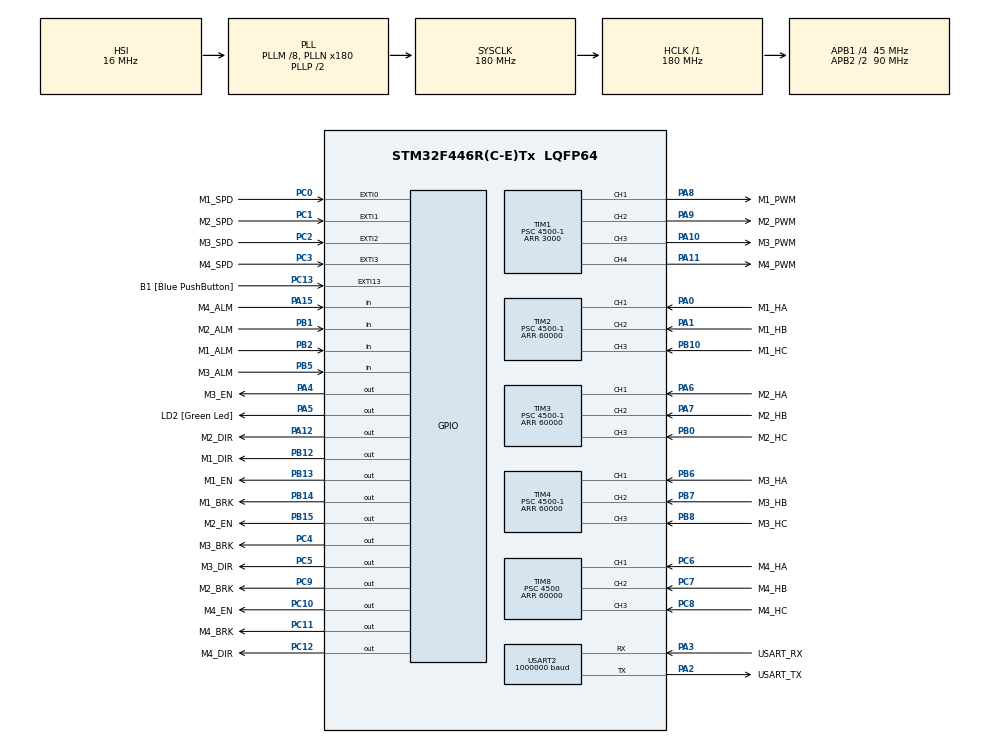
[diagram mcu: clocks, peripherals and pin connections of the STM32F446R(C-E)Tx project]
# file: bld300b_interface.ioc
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Dma.Request0=USART2_RX
Dma.Request1=USART2_TX
Dma.USART2_RX.0.Direction=DMA_PERIPH_TO_MEMORY
Dma.USART2_RX.0.FIFOMode=DMA_FIFOMODE_DISABLE
Dma.USART2_RX.0.Instance=DMA1_Stream5
Dma.USART2_RX.0.MemDataAlignment=DMA_MDATAALIGN_BYTE
Dma.USART2_RX.0.MemInc=DMA_MINC_ENABLE
Dma.USART2_RX.0.Mode=DMA_NORMAL
Dma.USART2_RX.0.PeriphDataAlignment=DMA_PDATAALIGN_BYTE
Dma.USART2_RX.0.PeriphInc=DMA_PINC_DISABLE
Dma.USART2_RX.0.Priority=DMA_PRIORITY_LOW
Dma.USART2_TX.1.Direction=DMA_MEMORY_TO_PERIPH
Dma.USART2_TX.1.FIFOMode=DMA_FIFOMODE_DISABLE
Dma.USART2_TX.1.Instance=DMA1_Stream6
Dma.USART2_TX.1.MemDataAlignment=DMA_MDATAALIGN_BYTE
Dma.USART2_TX.1.MemInc=DMA_MINC_ENABLE
Dma.USART2_TX.1.Mode=DMA_NORMAL
Dma.USART2_TX.1.PeriphDataAlignment=DMA_PDATAALIGN_BYTE
Dma.USART2_TX.1.PeriphInc=DMA_PINC_DISABLE
Dma.USART2_TX.1.Priority=DMA_PRIORITY_LOW
Mcu.Family=STM32F4
Mcu.Name=STM32F446R(C-E)Tx
Mcu.Package=LQFP64
NVIC.DMA1_Stream5_IRQn=true\:0\:0\:false\:false\:true\:false\:true
NVIC.DMA1_Stream6_IRQn=true\:0\:0\:false\:false\:true\:false\:true
NVIC.EXTI0_IRQn=true\:1\:0\:true\:false\:true\:true\:true
NVIC.EXTI1_IRQn=true\:1\:0\:true\:false\:true\:true\:true
NVIC.EXTI2_IRQn=true\:1\:0\:true\:false\:true\:true\:true
NVIC.EXTI3_IRQn=true\:1\:0\:true\:false\:true\:true\:true
NVIC.PriorityGroup=NVIC_PRIORITYGROUP_2
NVIC.TIM2_IRQn=true\:2\:0\:true\:false\:true\:true\:true
NVIC.TIM3_IRQn=true\:2\:0\:true\:false\:true\:true\:true
NVIC.TIM4_IRQn=true\:2\:0\:true\:false\:true\:true\:true
NVIC.TIM8_TRG_COM_TIM14_IRQn=true\:2\:0\:true\:false\:true\:false\:true
NVIC.TIM8_UP_TIM13_IRQn=true\:2\:0\:true\:false\:true\:false\:true
NVIC.USART2_IRQn=true\:1\:0\:true\:false\:true\:true\:true
PA0-WKUP.GPIO_Label=M1_HA
PA0-WKUP.Signal=S_TIM2_CH1_ETR
PA1.GPIO_Label=M1_HB
PA1.Signal=S_TIM2_CH2
PA10.GPIO_Label=M3_PWM
PA10.GPIO_PuPd=GPIO_PULLDOWN
PA10.Signal=S_TIM1_CH3
PA11.GPIO_Label=M4_PWM
PA11.GPIO_PuPd=GPIO_PULLDOWN
PA11.Signal=S_TIM1_CH4
PA12.GPIO_Label=M2_DIR
PA12.Signal=GPIO_Output
PA13.GPIO_Label=TMS
PA13.Mode=Trace_Asynchronous_SW
PA13.Signal=SYS_JTMS-SWDIO
PA14.GPIO_Label=TCK
PA14.Mode=Trace_Asynchronous_SW
PA14.Signal=SYS_JTCK-SWCLK
PA15.GPIO_Label=M4_ALM
PA15.Signal=GPIO_Input
PA2.GPIO_Label=USART_TX
PA2.Mode=Asynchronous
PA2.Signal=USART2_TX
PA3.GPIO_Label=USART_RX
PA3.Mode=Asynchronous
PA3.Signal=USART2_RX
PA4.GPIO_Label=M3_EN
PA4.Signal=GPIO_Output
PA5.GPIO_Label=LD2 [Green Led]
PA5.Signal=GPIO_Output
PA6.GPIO_Label=M2_HA
PA6.Signal=S_TIM3_CH1
PA7.GPIO_Label=M2_HB
PA7.Signal=S_TIM3_CH2
PA8.GPIO_Label=M1_PWM
PA8.GPIO_PuPd=GPIO_PULLDOWN
PA8.Signal=S_TIM1_CH1
PA9.GPIO_Label=M2_PWM
PA9.GPIO_PuPd=GPIO_PULLDOWN
PA9.Signal=S_TIM1_CH2
PB0.GPIO_Label=M2_HC
PB0.Signal=S_TIM3_CH3
PB1.GPIO_Label=M2_ALM
PB1.Signal=GPIO_Input
PB10.GPIO_Label=M1_HC
PB10.Signal=S_TIM2_CH3
PB12.GPIO_Label=M1_DIR
PB12.Signal=GPIO_Output
PB13.GPIO_Label=M1_EN
PB13.GPIO_PuPd=GPIO_PULLDOWN
PB13.Signal=GPIO_Output
PB14.GPIO_Label=M1_BRK
PB14.GPIO_PuPd=GPIO_PULLDOWN
PB14.Signal=GPIO_Output
PB15.GPIO_Label=M2_EN
PB15.Signal=GPIO_Output
PB2.GPIO_Label=M1_ALM
PB2.Signal=GPIO_Input
PB3.GPIO_Label=SWO
PB3.Mode=Trace_Asynchronous_SW
PB3.Signal=SYS_JTDO-SWO
PB5.GPIO_Label=M3_ALM
PB5.Signal=GPIO_Input
PB6.GPIO_Label=M3_HA
PB6.Signal=S_TIM4_CH1
PB7.GPIO_Label=M3_HB
PB7.Signal=S_TIM4_CH2
PB8.GPIO_Label=M3_HC
PB8.Signal=S_TIM4_CH3
PC0.GPIO_Label=M1_SPD
PC0.GPIO_ModeDefaultEXTI=GPIO_MODE_IT_RISING
PC0.GPIO_PuPd=GPIO_PULLDOWN
PC0.Signal=GPXTI0
PC1.GPIO_Label=M2_SPD
PC1.GPIO_ModeDefaultEXTI=GPIO_MODE_IT_RISING
PC1.GPIO_PuPd=GPIO_PULLDOWN
PC1.Signal=GPXTI1
PC10.GPIO_Label=M4_EN
PC10.Signal=GPIO_Output
PC11.GPIO_Label=M4_BRK
PC11.Signal=GPIO_Output
PC12.GPIO_Label=M4_DIR
PC12.Signal=GPIO_Output
PC13.GPIO_Label=B1 [Blue PushButton]
PC13.GPIO_ModeDefaultEXTI=GPIO_MODE_IT_FALLING
PC13.Signal=GPXTI13
PC14-OSC32_IN.Mode=LSE-External-Oscillator
PC14-OSC32_IN.Signal=RCC_OSC32_IN
PC15-OSC32_OUT.Mode=LSE-External-Oscillator
PC15-OSC32_OUT.Signal=RCC_OSC32_OUT
PC2.GPIO_Label=M3_SPD
PC2.GPIO_ModeDefaultEXTI=GPIO_MODE_IT_RISING
PC2.GPIO_PuPd=GPIO_PULLDOWN
PC2.Signal=GPXTI2
PC3.GPIO_Label=M4_SPD
PC3.GPIO_ModeDefaultEXTI=GPIO_MODE_IT_RISING
PC3.GPIO_PuPd=GPIO_PULLDOWN
PC3.Signal=GPXTI3
PC4.GPIO_Label=M3_BRK
PC4.Signal=GPIO_Output
PC5.GPIO_Label=M3_DIR
PC5.Signal=GPIO_Output
PC6.GPIO_Label=M4_HA
PC6.Signal=S_TIM8_CH1
PC7.GPIO_Label=M4_HB
PC7.Signal=S_TIM8_CH2
PC8.GPIO_Label=M4_HC
PC8.Signal=S_TIM8_CH3
PC9.GPIO_Label=M2_BRK
PC9.Signal=GPIO_Output
PH0-OSC_IN.Mode=HSE-External-Oscillator
PH0-OSC_IN.Signal=RCC_OSC_IN
PH1-OSC_OUT.Mode=HSE-External-Oscillator
PH1-OSC_OUT.Signal=RCC_OSC_OUT
ProjectManager.HeapSize=0x200
ProjectManager.StackSize=0x400
ProjectManager.TargetToolchain=TrueSTUDIO
RCC.AHBFreq_Value=180000000
RCC.APB1CLKDivider=RCC_HCLK_DIV4
RCC.APB1Freq_Value=45000000
RCC.APB1TimFreq_Value=90000000
RCC.APB2CLKDivider=RCC_HCLK_DIV2
RCC.APB2Freq_Value=90000000
RCC.APB2TimFreq_Value=180000000
RCC.CortexFreq_Value=180000000
RCC.FLatency-AdvancedSettings=FLASH_LATENCY_5
RCC.HCLKFreq_Value=180000000
RCC.HSE_VALUE=8000000
RCC.HSI_VALUE=16000000
RCC.PLLM=8
RCC.PLLN=180
RCC.SYSCLKFreq_VALUE=180000000
RCC.SYSCLKSource=RCC_SYSCLKSOURCE_PLLCLK
RCC.USBFreq_Value=180000000
RCC.VCOOutputFreq_Value=360000000
SH.S_TIM1_CH1.0=TIM1_CH1,PWM Generation1 CH1
SH.S_TIM1_CH2.0=TIM1_CH2,PWM Generation2 CH2
SH.S_TIM1_CH3.0=TIM1_CH3,PWM Generation3 CH3
SH.S_TIM1_CH4.0=TIM1_CH4,PWM Generation4 CH4
SH.S_TIM2_CH1_ETR.0=TIM2_CH1,Xored_Inputs_Hall_Sensor_Interface
SH.S_TIM2_CH2.0=TIM2_CH2,Xored_Inputs_Hall_Sensor_Interface
SH.S_TIM2_CH3.0=TIM2_CH3,Xored_Inputs_Hall_Sensor_Interface
SH.S_TIM3_CH1.0=TIM3_CH1,Xored_Inputs_Hall_Sensor_Interface
SH.S_TIM3_CH2.0=TIM3_CH2,Xored_Inputs_Hall_Sensor_Interface
SH.S_TIM3_CH3.0=TIM3_CH3,Xored_Inputs_Hall_Sensor_Interface
SH.S_TIM4_CH1.0=TIM4_CH1,Xored_Inputs_Hall_Sensor_Interface
SH.S_TIM4_CH2.0=TIM4_CH2,Xored_Inputs_Hall_Sensor_Interface
SH.S_TIM4_CH3.0=TIM4_CH3,Xored_Inputs_Hall_Sensor_Interface
SH.S_TIM8_CH1.0=TIM8_CH1,Xored_Inputs_Hall_Sensor_Interface
SH.S_TIM8_CH2.0=TIM8_CH2,Xored_Inputs_Hall_Sensor_Interface
SH.S_TIM8_CH3.0=TIM8_CH3,Xored_Inputs_Hall_Sensor_Interface
TIM1.Channel-PWM\ Generation1\ CH1=TIM_CHANNEL_1
TIM1.Channel-PWM\ Generation2\ CH2=TIM_CHANNEL_2
TIM1.Channel-PWM\ Generation3\ CH3=TIM_CHANNEL_3
TIM1.Channel-PWM\ Generation4\ CH4=TIM_CHANNEL_4
TIM1.ClockDivision=TIM_CLOCKDIVISION_DIV4
TIM1.Period=3000
TIM1.Prescaler=4500-1
TIM1.Pulse-PWM\ Generation1\ CH1=750
TIM2.ClockDivision=TIM_CLOCKDIVISION_DIV4
TIM2.IC1Filter=3
TIM2.Period=60000
TIM2.Prescaler=4500-1
TIM3.ClockDivision=TIM_CLOCKDIVISION_DIV4
TIM3.IC1Filter=3
TIM3.Period=60000
TIM3.Prescaler=4500-1
TIM4.ClockDivision=TIM_CLOCKDIVISION_DIV4
TIM4.IC1Filter=3
TIM4.Period=60000
TIM4.Prescaler=4500-1
TIM5.ClockDivision=TIM_CLOCKDIVISION_DIV4
TIM5.Period=0xffffffff
TIM5.Prescaler=45-1
TIM8.ClockDivision=TIM_CLOCKDIVISION_DIV4
TIM8.IC1Filter=3
TIM8.Period=60000
TIM8.Prescaler=4500
USART2.BaudRate=1000000
USART2.VirtualMode=VM_ASYNC
VP_TIM5_VS_ClockSourceINT.Mode=Internal
board=NUCLEO-F446RE

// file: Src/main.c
/* USER CODE BEGIN Header */
/**
  ******************************************************************************
  * @file           : main.c
  * @brief          : Main program body
  ******************************************************************************
  * @attention
  *
  * <h2><center>&copy; Copyright (c) 2019 STMicroelectronics.
  * All rights reserved.</center></h2>
  *
  * This software component is licensed by ST under BSD 3-Clause license,
  * the "License"; You may not use this file except in compliance with the
  * License. You may obtain a copy of the License at:
  *                        opensource.org/licenses/BSD-3-Clause
  *
  ******************************************************************************
  */
/* USER CODE END Header */

#include "main.h"

/* USER CODE BEGIN Includes */
#include "firmware.h"
/* USER CODE END Includes */

TIM_HandleTypeDef htim1;
TIM_HandleTypeDef htim2;
TIM_HandleTypeDef htim3;
TIM_HandleTypeDef htim4;
TIM_HandleTypeDef htim5;
TIM_HandleTypeDef htim8;

UART_HandleTypeDef huart2;

void SystemClock_Config(void);
static void MX_GPIO_Init(void);
static void MX_USART2_UART_Init(void);
static void MX_TIM1_Init(void);
static void MX_TIM2_Init(void);
static void MX_TIM3_Init(void);
static void MX_TIM4_Init(void);
static void MX_TIM8_Init(void);
static void MX_TIM5_Init(void);

int main(void)
{

  /* MCU Configuration--------------------------------------------------------*/

  /* Reset of all peripherals, Initializes the Flash interface and the Systick. */
  HAL_Init();

  /* Configure the system clock */
  SystemClock_Config();

  /* Initialize all configured peripherals */
  MX_GPIO_Init();
  MX_USART2_UART_Init();
  MX_TIM1_Init();
  MX_TIM2_Init();
  MX_TIM3_Init();
  MX_TIM4_Init();
  MX_TIM8_Init();
  MX_TIM5_Init();
  /* USER CODE BEGIN 2 */

  /* Init firmware */
  Firmware_Init();

  /* USER CODE END 2 */

  /* Infinite loop */
  /* USER CODE BEGIN WHILE */
  while (1)
  {
    /* Update firmware */
    Firmware_Update();
    /* USER CODE END WHILE */

  }
}

void SystemClock_Config(void)
{
  RCC_OscInitTypeDef RCC_OscInitStruct = {0};
  RCC_ClkInitTypeDef RCC_ClkInitStruct = {0};

  /** Configure the main internal regulator output voltage
  */
  __HAL_RCC_PWR_CLK_ENABLE();
  __HAL_PWR_VOLTAGESCALING_CONFIG(PWR_REGULATOR_VOLTAGE_SCALE1);
  /** Initializes the CPU, AHB and APB busses clocks
  */
  RCC_OscInitStruct.OscillatorType = RCC_OSCILLATORTYPE_HSI;
  RCC_OscInitStruct.HSIState = RCC_HSI_ON;
  RCC_OscInitStruct.HSICalibrationValue = RCC_HSICALIBRATION_DEFAULT;
  RCC_OscInitStruct.PLL.PLLState = RCC_PLL_ON;
  RCC_OscInitStruct.PLL.PLLSource = RCC_PLLSOURCE_HSI;
  RCC_OscInitStruct.PLL.PLLM = 8;
  RCC_OscInitStruct.PLL.PLLN = 180;
  RCC_OscInitStruct.PLL.PLLP = RCC_PLLP_DIV2;
  RCC_OscInitStruct.PLL.PLLQ = 2;
  RCC_OscInitStruct.PLL.PLLR = 2;
  if (HAL_RCC_OscConfig(&RCC_OscInitStruct) != HAL_OK)
  {
    Error_Handler();
  }
  /** Activate the Over-Drive mode
  */
  if (HAL_PWREx_EnableOverDrive() != HAL_OK)
  {
    Error_Handler();
  }
  /** Initializes the CPU, AHB and APB busses clocks
  */
  RCC_ClkInitStruct.ClockType = RCC_CLOCKTYPE_HCLK|RCC_CLOCKTYPE_SYSCLK
                              |RCC_CLOCKTYPE_PCLK1|RCC_CLOCKTYPE_PCLK2;
  RCC_ClkInitStruct.SYSCLKSource = RCC_SYSCLKSOURCE_PLLCLK;
  RCC_ClkInitStruct.AHBCLKDivider = RCC_SYSCLK_DIV1;
  RCC_ClkInitStruct.APB1CLKDivider = RCC_HCLK_DIV4;
  RCC_ClkInitStruct.APB2CLKDivider = RCC_HCLK_DIV2;

  if (HAL_RCC_ClockConfig(&RCC_ClkInitStruct, FLASH_LATENCY_5) != HAL_OK)
  {
    Error_Handler();
  }
}

static void MX_TIM1_Init(void)
{

  TIM_MasterConfigTypeDef sMasterConfig = {0};
  TIM_OC_InitTypeDef sConfigOC = {0};
  TIM_BreakDeadTimeConfigTypeDef sBreakDeadTimeConfig = {0};

  htim1.Instance = TIM1;
  htim1.Init.Prescaler = 4500;
  htim1.Init.CounterMode = TIM_COUNTERMODE_UP;
  htim1.Init.Period = 3000;
  htim1.Init.ClockDivision = TIM_CLOCKDIVISION_DIV4;
  htim1.Init.RepetitionCounter = 0;
  htim1.Init.AutoReloadPreload = TIM_AUTORELOAD_PRELOAD_DISABLE;
  if (HAL_TIM_PWM_Init(&htim1) != HAL_OK)
  {
    Error_Handler();
  }
  sMasterConfig.MasterOutputTrigger = TIM_TRGO_RESET;
  sMasterConfig.MasterSlaveMode = TIM_MASTERSLAVEMODE_DISABLE;
  if (HAL_TIMEx_MasterConfigSynchronization(&htim1, &sMasterConfig) != HAL_OK)
  {
    Error_Handler();
  }
  sConfigOC.OCMode = TIM_OCMODE_PWM1;
  sConfigOC.Pulse = 750;
  sConfigOC.OCPolarity = TIM_OCPOLARITY_HIGH;
  sConfigOC.OCNPolarity = TIM_OCNPOLARITY_HIGH;
  sConfigOC.OCFastMode = TIM_OCFAST_DISABLE;
  sConfigOC.OCIdleState = TIM_OCIDLESTATE_RESET;
  sConfigOC.OCNIdleState = TIM_OCNIDLESTATE_RESET;
  if (HAL_TIM_PWM_ConfigChannel(&htim1, &sConfigOC, TIM_CHANNEL_1) != HAL_OK)
  {
    Error_Handler();
  }
  sConfigOC.Pulse = 0;
  if (HAL_TIM_PWM_ConfigChannel(&htim1, &sConfigOC, TIM_CHANNEL_2) != HAL_OK)
  {
    Error_Handler();
  }
  if (HAL_TIM_PWM_ConfigChannel(&htim1, &sConfigOC, TIM_CHANNEL_3) != HAL_OK)
  {
    Error_Handler();
  }
  if (HAL_TIM_PWM_ConfigChannel(&htim1, &sConfigOC, TIM_CHANNEL_4) != HAL_OK)
  {
    Error_Handler();
  }
  sBreakDeadTimeConfig.OffStateRunMode = TIM_OSSR_DISABLE;
  sBreakDeadTimeConfig.OffStateIDLEMode = TIM_OSSI_DISABLE;
  sBreakDeadTimeConfig.LockLevel = TIM_LOCKLEVEL_OFF;
  sBreakDeadTimeConfig.DeadTime = 0;
  sBreakDeadTimeConfig.BreakState = TIM_BREAK_DISABLE;
  sBreakDeadTimeConfig.BreakPolarity = TIM_BREAKPOLARITY_HIGH;
  sBreakDeadTimeConfig.AutomaticOutput = TIM_AUTOMATICOUTPUT_DISABLE;
  if (HAL_TIMEx_ConfigBreakDeadTime(&htim1, &sBreakDeadTimeConfig) != HAL_OK)
  {
    Error_Handler();
  }
  HAL_TIM_MspPostInit(&htim1);

}

static void MX_TIM2_Init(void)
{

  TIM_HallSensor_InitTypeDef sConfig = {0};
  TIM_MasterConfigTypeDef sMasterConfig = {0};

  htim2.Instance = TIM2;
  htim2.Init.Prescaler = 4500;
  htim2.Init.CounterMode = TIM_COUNTERMODE_UP;
  htim2.Init.Period = 60000;
  htim2.Init.ClockDivision = TIM_CLOCKDIVISION_DIV4;
  htim2.Init.AutoReloadPreload = TIM_AUTORELOAD_PRELOAD_DISABLE;
  sConfig.IC1Polarity = TIM_ICPOLARITY_RISING;
  sConfig.IC1Prescaler = TIM_ICPSC_DIV1;
  sConfig.IC1Filter = 3;
  sConfig.Commutation_Delay = 0;
  if (HAL_TIMEx_HallSensor_Init(&htim2, &sConfig) != HAL_OK)
  {
    Error_Handler();
  }
  sMasterConfig.MasterOutputTrigger = TIM_TRGO_OC2REF;
  sMasterConfig.MasterSlaveMode = TIM_MASTERSLAVEMODE_DISABLE;
  if (HAL_TIMEx_MasterConfigSynchronization(&htim2, &sMasterConfig) != HAL_OK)
  {
    Error_Handler();
  }

}

static void MX_TIM3_Init(void)
{

  TIM_HallSensor_InitTypeDef sConfig = {0};
  TIM_MasterConfigTypeDef sMasterConfig = {0};

  htim3.Instance = TIM3;
  htim3.Init.Prescaler = 4500;
  htim3.Init.CounterMode = TIM_COUNTERMODE_UP;
  htim3.Init.Period = 60000;
  htim3.Init.ClockDivision = TIM_CLOCKDIVISION_DIV4;
  htim3.Init.AutoReloadPreload = TIM_AUTORELOAD_PRELOAD_DISABLE;
  sConfig.IC1Polarity = TIM_ICPOLARITY_RISING;
  sConfig.IC1Prescaler = TIM_ICPSC_DIV1;
  sConfig.IC1Filter = 3;
  sConfig.Commutation_Delay = 0;
  if (HAL_TIMEx_HallSensor_Init(&htim3, &sConfig) != HAL_OK)
  {
    Error_Handler();
  }
  sMasterConfig.MasterOutputTrigger = TIM_TRGO_OC2REF;
  sMasterConfig.MasterSlaveMode = TIM_MASTERSLAVEMODE_DISABLE;
  if (HAL_TIMEx_MasterConfigSynchronization(&htim3, &sMasterConfig) != HAL_OK)
  {
    Error_Handler();
  }

}

static void MX_TIM4_Init(void)
{

  TIM_HallSensor_InitTypeDef sConfig = {0};
  TIM_MasterConfigTypeDef sMasterConfig = {0};

  htim4.Instance = TIM4;
  htim4.Init.Prescaler = 4500;
  htim4.Init.CounterMode = TIM_COUNTERMODE_UP;
  htim4.Init.Period = 60000;
  htim4.Init.ClockDivision = TIM_CLOCKDIVISION_DIV4;
  htim4.Init.AutoReloadPreload = TIM_AUTORELOAD_PRELOAD_DISABLE;
  sConfig.IC1Polarity = TIM_ICPOLARITY_RISING;
  sConfig.IC1Prescaler = TIM_ICPSC_DIV1;
  sConfig.IC1Filter = 3;
  sConfig.Commutation_Delay = 0;
  if (HAL_TIMEx_HallSensor_Init(&htim4, &sConfig) != HAL_OK)
  {
    Error_Handler();
  }
  sMasterConfig.MasterOutputTrigger = TIM_TRGO_OC2REF;
  sMasterConfig.MasterSlaveMode = TIM_MASTERSLAVEMODE_DISABLE;
  if (HAL_TIMEx_MasterConfigSynchronization(&htim4, &sMasterConfig) != HAL_OK)
  {
    Error_Handler();
  }

}

static void MX_TIM5_Init(void)
{

  TIM_ClockConfigTypeDef sClockSourceConfig = {0};
  TIM_MasterConfigTypeDef sMasterConfig = {0};

  htim5.Instance = TIM5;
  htim5.Init.Prescaler = 45;
  htim5.Init.CounterMode = TIM_COUNTERMODE_UP;
  htim5.Init.Period = 4294967295;
  htim5.Init.ClockDivision = TIM_CLOCKDIVISION_DIV4;
  htim5.Init.AutoReloadPreload = TIM_AUTORELOAD_PRELOAD_DISABLE;
  if (HAL_TIM_Base_Init(&htim5) != HAL_OK)
  {
    Error_Handler();
  }
  sClockSourceConfig.ClockSource = TIM_CLOCKSOURCE_INTERNAL;
  if (HAL_TIM_ConfigClockSource(&htim5, &sClockSourceConfig) != HAL_OK)
  {
    Error_Handler();
  }
  sMasterConfig.MasterOutputTrigger = TIM_TRGO_RESET;
  sMasterConfig.MasterSlaveMode = TIM_MASTERSLAVEMODE_DISABLE;
  if (HAL_TIMEx_MasterConfigSynchronization(&htim5, &sMasterConfig) != HAL_OK)
  {
    Error_Handler();
  }

}

static void MX_TIM8_Init(void)
{

  TIM_HallSensor_InitTypeDef sConfig = {0};
  TIM_MasterConfigTypeDef sMasterConfig = {0};

  htim8.Instance = TIM8;
  htim8.Init.Prescaler = 4500;
  htim8.Init.CounterMode = TIM_COUNTERMODE_UP;
  htim8.Init.Period = 60000;
  htim8.Init.ClockDivision = TIM_CLOCKDIVISION_DIV4;
  htim8.Init.RepetitionCounter = 0;
  htim8.Init.AutoReloadPreload = TIM_AUTORELOAD_PRELOAD_DISABLE;
  sConfig.IC1Polarity = TIM_ICPOLARITY_RISING;
  sConfig.IC1Prescaler = TIM_ICPSC_DIV1;
  sConfig.IC1Filter = 3;
  sConfig.Commutation_Delay = 0;
  if (HAL_TIMEx_HallSensor_Init(&htim8, &sConfig) != HAL_OK)
  {
    Error_Handler();
  }
  sMasterConfig.MasterOutputTrigger = TIM_TRGO_OC2REF;
  sMasterConfig.MasterSlaveMode = TIM_MASTERSLAVEMODE_DISABLE;
  if (HAL_TIMEx_MasterConfigSynchronization(&htim8, &sMasterConfig) != HAL_OK)
  {
    Error_Handler();
  }

}

static void MX_USART2_UART_Init(void)
{

  huart2.Instance = USART2;
  huart2.Init.BaudRate = 115200;
  huart2.Init.WordLength = UART_WORDLENGTH_8B;
  huart2.Init.StopBits = UART_STOPBITS_1;
  huart2.Init.Parity = UART_PARITY_NONE;
  huart2.Init.Mode = UART_MODE_TX_RX;
  huart2.Init.HwFlowCtl = UART_HWCONTROL_NONE;
  huart2.Init.OverSampling = UART_OVERSAMPLING_16;
  if (HAL_UART_Init(&huart2) != HAL_OK)
  {
    Error_Handler();
  }

}

static void MX_GPIO_Init(void)
{
  GPIO_InitTypeDef GPIO_InitStruct = {0};

  /* GPIO Ports Clock Enable */
  __HAL_RCC_GPIOC_CLK_ENABLE();
  __HAL_RCC_GPIOH_CLK_ENABLE();
  __HAL_RCC_GPIOA_CLK_ENABLE();
  __HAL_RCC_GPIOB_CLK_ENABLE();

  /*Configure GPIO pin Output Level */
  HAL_GPIO_WritePin(GPIOA, M3_EN_Pin|LD2_Pin|M2_DIR_Pin, GPIO_PIN_RESET);

  /*Configure GPIO pin Output Level */
  HAL_GPIO_WritePin(GPIOC, M3_BRK_Pin|M3_DIR_Pin|M2_BRK_Pin|M4_EN_Pin
                          |M4_BRK_Pin|M4_DIR_Pin, GPIO_PIN_RESET);

  /*Configure GPIO pin Output Level */
  HAL_GPIO_WritePin(GPIOB, M1_DIR_Pin|M1_EN_Pin|M1_BRK_Pin|M2_EN_Pin, GPIO_PIN_RESET);

  /*Configure GPIO pin : B1_Pin */
  GPIO_InitStruct.Pin = B1_Pin;
  GPIO_InitStruct.Mode = GPIO_MODE_IT_FALLING;
  GPIO_InitStruct.Pull = GPIO_NOPULL;
  HAL_GPIO_Init(B1_GPIO_Port, &GPIO_InitStruct);

  /*Configure GPIO pins : M1_SPD_Pin M2_SPD_Pin M3_SPD_Pin M4_SPD_Pin */
  GPIO_InitStruct.Pin = M1_SPD_Pin|M2_SPD_Pin|M3_SPD_Pin|M4_SPD_Pin;
  GPIO_InitStruct.Mode = GPIO_MODE_IT_RISING;
  GPIO_InitStruct.Pull = GPIO_PULLUP;
  HAL_GPIO_Init(GPIOC, &GPIO_InitStruct);

  /*Configure GPIO pins : M3_EN_Pin LD2_Pin M2_DIR_Pin */
  GPIO_InitStruct.Pin = M3_EN_Pin|LD2_Pin|M2_DIR_Pin;
  GPIO_InitStruct.Mode = GPIO_MODE_OUTPUT_PP;
  GPIO_InitStruct.Pull = GPIO_NOPULL;
  GPIO_InitStruct.Speed = GPIO_SPEED_FREQ_LOW;
  HAL_GPIO_Init(GPIOA, &GPIO_InitStruct);

  /*Configure GPIO pins : M3_BRK_Pin M3_DIR_Pin M2_BRK_Pin M4_EN_Pin
                           M4_BRK_Pin M4_DIR_Pin */
  GPIO_InitStruct.Pin = M3_BRK_Pin|M3_DIR_Pin|M2_BRK_Pin|M4_EN_Pin
                          |M4_BRK_Pin|M4_DIR_Pin;
  GPIO_InitStruct.Mode = GPIO_MODE_OUTPUT_PP;
  GPIO_InitStruct.Pull = GPIO_NOPULL;
  GPIO_InitStruct.Speed = GPIO_SPEED_FREQ_LOW;
  HAL_GPIO_Init(GPIOC, &GPIO_InitStruct);

  /*Configure GPIO pins : M2_ALM_Pin M1_ALM_Pin M3_ALM_Pin */
  GPIO_InitStruct.Pin = M2_ALM_Pin|M1_ALM_Pin|M3_ALM_Pin;
  GPIO_InitStruct.Mode = GPIO_MODE_INPUT;
  GPIO_InitStruct.Pull = GPIO_NOPULL;
  HAL_GPIO_Init(GPIOB, &GPIO_InitStruct);

  /*Configure GPIO pins : M1_DIR_Pin M2_EN_Pin */
  GPIO_InitStruct.Pin = M1_DIR_Pin|M2_EN_Pin;
  GPIO_InitStruct.Mode = GPIO_MODE_OUTPUT_PP;
  GPIO_InitStruct.Pull = GPIO_NOPULL;
  GPIO_InitStruct.Speed = GPIO_SPEED_FREQ_LOW;
  HAL_GPIO_Init(GPIOB, &GPIO_InitStruct);

  /*Configure GPIO pins : M1_EN_Pin M1_BRK_Pin */
  GPIO_InitStruct.Pin = M1_EN_Pin|M1_BRK_Pin;
  GPIO_InitStruct.Mode = GPIO_MODE_OUTPUT_PP;
  GPIO_InitStruct.Pull = GPIO_PULLDOWN;
  GPIO_InitStruct.Speed = GPIO_SPEED_FREQ_LOW;
  HAL_GPIO_Init(GPIOB, &GPIO_InitStruct);

  /*Configure GPIO pin : M4_ALM_Pin */
  GPIO_InitStruct.Pin = M4_ALM_Pin;
  GPIO_InitStruct.Mode = GPIO_MODE_INPUT;
  GPIO_InitStruct.Pull = GPIO_NOPULL;
  HAL_GPIO_Init(M4_ALM_GPIO_Port, &GPIO_InitStruct);

  /* EXTI interrupt init*/
  HAL_NVIC_SetPriority(EXTI0_IRQn, 1, 0);
  HAL_NVIC_EnableIRQ(EXTI0_IRQn);

  HAL_NVIC_SetPriority(EXTI1_IRQn, 1, 0);
  HAL_NVIC_EnableIRQ(EXTI1_IRQn);

  HAL_NVIC_SetPriority(EXTI2_IRQn, 1, 0);
  HAL_NVIC_EnableIRQ(EXTI2_IRQn);

  HAL_NVIC_SetPriority(EXTI3_IRQn, 1, 0);
  HAL_NVIC_EnableIRQ(EXTI3_IRQn);

}

void Error_Handler(void)
{
  /* USER CODE BEGIN Error_Handler_Debug */
  /* User can add his own implementation to report the HAL error return state */
  while(1)
  {
    HAL_GPIO_TogglePin(LD2_GPIO_Port, LD2_Pin);
    HAL_Delay(50u);
  }
  /* USER CODE END Error_Handler_Debug */
}

/************************ (C) COPYRIGHT STMicroelectronics *****END OF FILE****/
